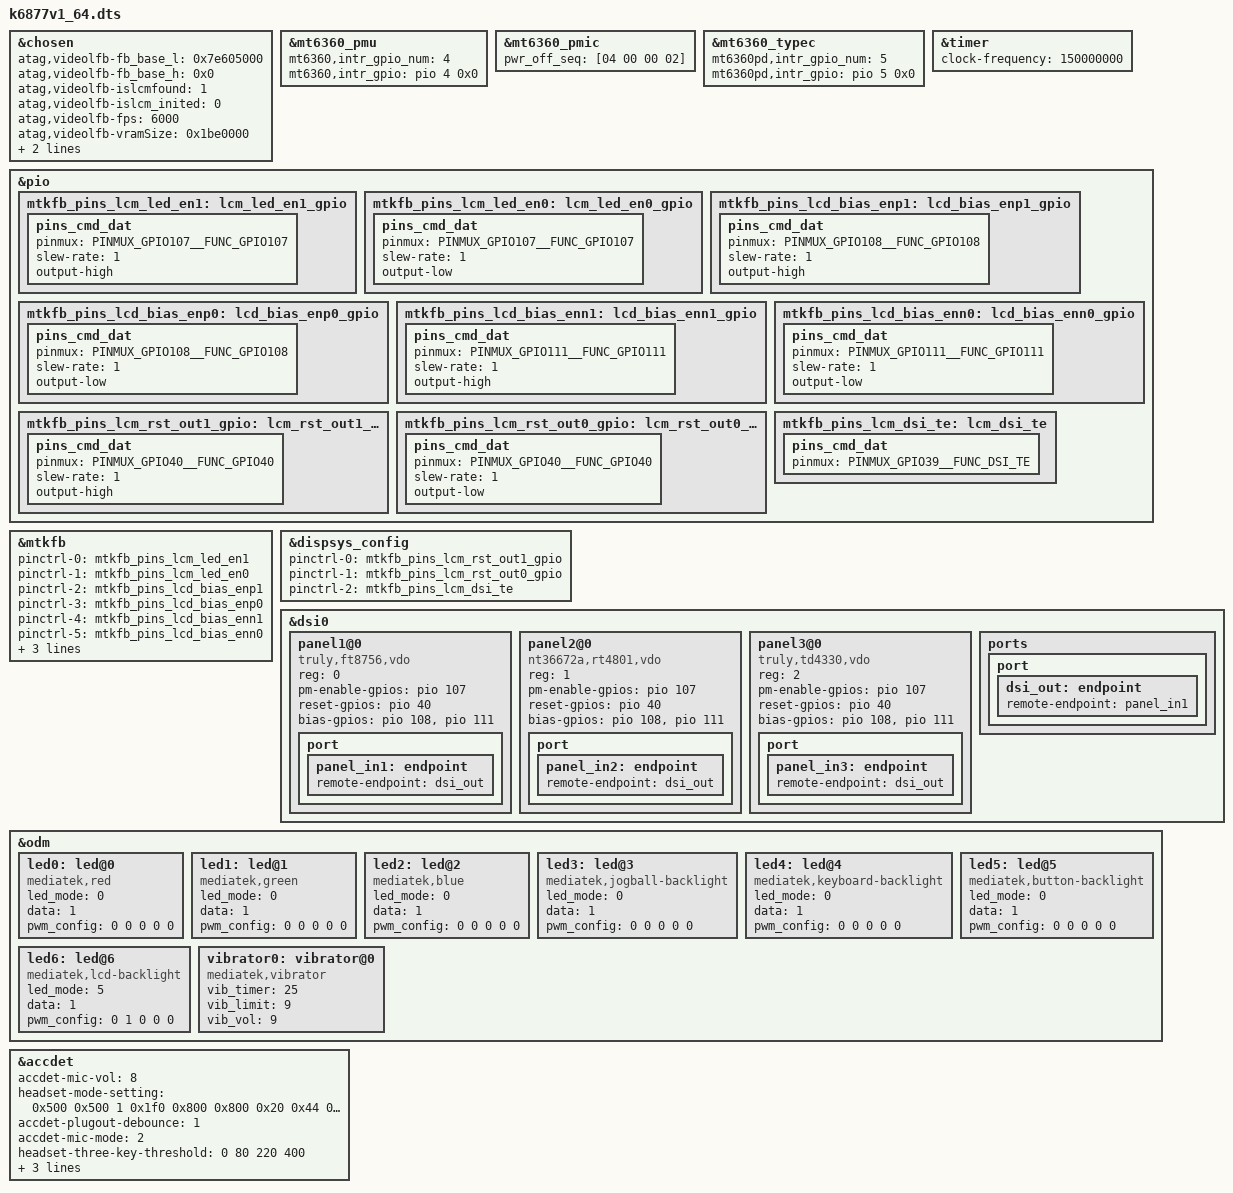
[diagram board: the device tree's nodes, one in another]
/*
 * Mediatek's mt6853 SoC device tree source
 *
 * Copyright (C) 2016 MediaTek Inc.
 *
 * This program is free software; you can redistribute it and/or modify
 * it under the terms of the GNU General Public License version 2 as
 * published by the Free Software Foundation.
 *
 * This program is distributed in the hope that it will be useful,
 * but WITHOUT ANY WARRANTY; without even the implied warranty of
 * MERCHANTABILITY or FITNESS FOR A PARTICULAR PURPOSE.
 * See http://www.gnu.org/licenses/gpl-2.0.html for more details.
 */
/dts-v1/;
/plugin/;
#include <dt-bindings/interrupt-controller/irq.h>
#include <dt-bindings/interrupt-controller/arm-gic.h>
#include <dt-bindings/pinctrl/mt6877-pinfunc.h>

/* chosen */
&chosen {
	atag,videolfb-fb_base_l = <0x7e605000>;
	atag,videolfb-fb_base_h = <0x0>;
	atag,videolfb-islcmfound = <1>;
	atag,videolfb-islcm_inited = <0>;
	atag,videolfb-fps= <6000>;
	atag,videolfb-vramSize= <0x1be0000>;
	atag,videolfb-lcmname=
		"td4330_fhdp_dsi_cmd_auo_rt4831_drv";
};

&mt6360_pmu {
	mt6360,intr_gpio_num = <4>; /* direct defined GPIO num */
	mt6360,intr_gpio = <&pio 4 0x0>;
};

&mt6360_pmic {
	pwr_off_seq = [04 00 00 02];
};

&mt6360_typec {
	mt6360pd,intr_gpio_num = <5>; /* direct defined GPIO num */
	mt6360pd,intr_gpio = <&pio 5 0x0>;
};

&timer {
	clock-frequency = <150000000>;
};

&pio {
	mtkfb_pins_lcm_led_en1: lcm_led_en1_gpio {
		pins_cmd_dat {
			pinmux = <PINMUX_GPIO107__FUNC_GPIO107>;
			slew-rate = <1>;
			output-high;
		};
	};

	mtkfb_pins_lcm_led_en0: lcm_led_en0_gpio {
		pins_cmd_dat {
			pinmux = <PINMUX_GPIO107__FUNC_GPIO107>;
			slew-rate = <1>;
			output-low;
		};
	};

	mtkfb_pins_lcd_bias_enp1: lcd_bias_enp1_gpio {
		pins_cmd_dat {
			pinmux = <PINMUX_GPIO108__FUNC_GPIO108>;
			slew-rate = <1>;
			output-high;
		};
	};

	mtkfb_pins_lcd_bias_enp0: lcd_bias_enp0_gpio {
		pins_cmd_dat {
			pinmux = <PINMUX_GPIO108__FUNC_GPIO108>;
			slew-rate = <1>;
			output-low;
		};
	};

	mtkfb_pins_lcd_bias_enn1: lcd_bias_enn1_gpio {
		pins_cmd_dat {
			pinmux = <PINMUX_GPIO111__FUNC_GPIO111>;
			slew-rate = <1>;
			output-high;
		};
	};

	mtkfb_pins_lcd_bias_enn0: lcd_bias_enn0_gpio {
		pins_cmd_dat {
			pinmux = <PINMUX_GPIO111__FUNC_GPIO111>;
			slew-rate = <1>;
			output-low;
		};
	};

	mtkfb_pins_lcm_rst_out1_gpio: lcm_rst_out1_gpio {
		pins_cmd_dat {
			pinmux = <PINMUX_GPIO40__FUNC_GPIO40>;
			slew-rate = <1>;
			output-high;
		};
	};

	mtkfb_pins_lcm_rst_out0_gpio: lcm_rst_out0_gpio {
		pins_cmd_dat {
			pinmux = <PINMUX_GPIO40__FUNC_GPIO40>;
			slew-rate = <1>;
			output-low;
		};
	};
	mtkfb_pins_lcm_dsi_te: lcm_dsi_te {
		pins_cmd_dat {
			pinmux = <PINMUX_GPIO39__FUNC_DSI_TE>;
		};
	};
};

&mtkfb {
	pinctrl-names = "lcm_led_en1_gpio", "lcm_led_en0_gpio",
		"lcd_bias_enp1_gpio", "lcd_bias_enp0_gpio",
		"lcd_bias_enn1_gpio", "lcd_bias_enn0_gpio",
		"lcm_rst_out1_gpio", "lcm_rst_out0_gpio",
		"mode_te_te";
	pinctrl-0 = <&mtkfb_pins_lcm_led_en1>;
	pinctrl-1 = <&mtkfb_pins_lcm_led_en0>;
	pinctrl-2 = <&mtkfb_pins_lcd_bias_enp1>;
	pinctrl-3 = <&mtkfb_pins_lcd_bias_enp0>;
	pinctrl-4 = <&mtkfb_pins_lcd_bias_enn1>;
	pinctrl-5 = <&mtkfb_pins_lcd_bias_enn0>;
	pinctrl-6 = <&mtkfb_pins_lcm_rst_out1_gpio>;
	pinctrl-7 = <&mtkfb_pins_lcm_rst_out0_gpio>;
	pinctrl-8 = <&mtkfb_pins_lcm_dsi_te>;
	status = "okay";
};
&dispsys_config {
	pinctrl-names =
		"lcm_rst_out1_gpio", "lcm_rst_out0_gpio",
		"mode_te_te";
	pinctrl-0 = <&mtkfb_pins_lcm_rst_out1_gpio>;
	pinctrl-1 = <&mtkfb_pins_lcm_rst_out0_gpio>;
	pinctrl-2 = <&mtkfb_pins_lcm_dsi_te>;
	status = "okay";
};

&dsi0 {
	status = "okay";
	#address-cells = <1>;
	#size-cells = <0>;
	panel1@0 {
		compatible = "truly,ft8756,vdo";
		reg = <0>;
		pm-enable-gpios = <&pio 107 0>;
		reset-gpios = <&pio 40 0>;
		bias-gpios = <&pio 108 0>,
			<&pio 111 0>;
		pinctrl-names = "default";
		port {
			panel_in1: endpoint {
				remote-endpoint = <&dsi_out>;
			};
		};
	};
	panel2@0 {
		compatible = "nt36672a,rt4801,vdo";
		reg = <1>;
		pm-enable-gpios = <&pio 107 0>;
		reset-gpios = <&pio 40 0>;
		bias-gpios = <&pio 108 0>,
			<&pio 111 0>;
		pinctrl-names = "default";
		port {
			panel_in2: endpoint {
				remote-endpoint = <&dsi_out>;
			};
		};
	};
	panel3@0 {
		compatible = "truly,td4330,vdo";
		reg = <2>;
		pm-enable-gpios = <&pio 107 0>;
		reset-gpios = <&pio 40 0>;
		bias-gpios = <&pio 108 0>,
			<&pio 111 0>;
		pinctrl-names = "default";
		port {
			panel_in3: endpoint {
				remote-endpoint = <&dsi_out>;
			};
		};
	};
	ports {
		port {
			dsi_out: endpoint {
				remote-endpoint = <&panel_in1>;
			};
		};
	};
};

&odm {
	led0:led@0 {
		compatible = "mediatek,red";
		led_mode = <0>;
		data = <1>;
		pwm_config = <0 0 0 0 0>;
	};
	led1:led@1 {
		compatible = "mediatek,green";
		led_mode = <0>;
		data = <1>;
		pwm_config = <0 0 0 0 0>;
	};
	led2:led@2 {
		compatible = "mediatek,blue";
		led_mode = <0>;
		data = <1>;
		pwm_config = <0 0 0 0 0>;
	};
	led3:led@3 {
		compatible = "mediatek,jogball-backlight";
		led_mode = <0>;
		data = <1>;
		pwm_config = <0 0 0 0 0>;
	};
	led4:led@4 {
		compatible = "mediatek,keyboard-backlight";
		led_mode = <0>;
		data = <1>;
		pwm_config = <0 0 0 0 0>;
	};
	led5:led@5 {
		compatible = "mediatek,button-backlight";
		led_mode = <0>;
		data = <1>;
		pwm_config = <0 0 0 0 0>;
	};
	led6:led@6 {
		compatible = "mediatek,lcd-backlight";
		led_mode = <5>;
		data = <1>;
		pwm_config = <0 1 0 0 0>;
	};
	vibrator0:vibrator@0 {
		compatible = "mediatek,vibrator";
		vib_timer = <25>;
		vib_limit = <9>;
		vib_vol= <9>;
	};
};

&accdet {
	/* accdet micbias voltage: 0x09:2.85v 0x08:2.8v 0x07,
	 * 2.7v;0x05,2.5v;0x02,1.9v
	 */
	accdet-mic-vol = <8>;
	/* accdet pwm_width, pwm_thresh, fall_delay, rise_delay
	 * debounce0, debounce1, debounce3, debounce4
	 * eint pwm_width, eint pwm_thresh
	 * eint deb(debounce0, debounce1, debounce2, debounce3), inv_debounce
	 */
	headset-mode-setting = <0x500 0x500 1 0x1f0
				0x800 0x800 0x20 0x44
				0x4 0x1
				0x5 0x3 0x3 0x5 0xe>;
	accdet-plugout-debounce = <1>;
	/*1:ACC mode, 2:low cost without in bias, 6:low cost with in bias*/
	accdet-mic-mode = <2>;
	/*0--MD_MAX--UP_MAX--DW_MAX*/
	headset-three-key-threshold = <0 80 220 400>;
	headset-three-key-threshold-CDD = <0 121 192 600>;
	/*0--MD_MAX--VOICE_MAX--UP_MAX--DW_MAX*/
	headset-four-key-threshold = <0 58 121 192 400>;

	/* select VTH to 2v and 500k, use internal resitance */
	eint_use_ext_res = <0>;
	status = "okay";
};

#include "mediatek/cust_mt6877_touch_1080x2300.dtsi"
/*End of this file, DO NOT ADD ANYTHING HERE*/

